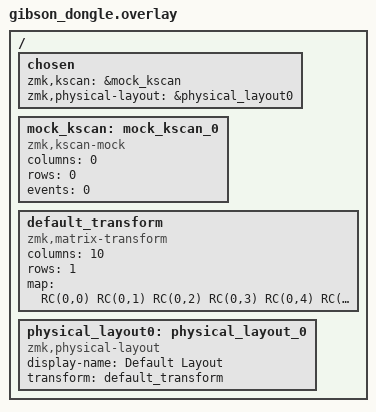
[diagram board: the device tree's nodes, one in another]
#include <dt-bindings/zmk/matrix_transform.h>

/ {
    chosen {
        zmk,kscan = &mock_kscan;
        zmk,physical-layout = &physical_layout0;
    };

    mock_kscan: mock_kscan_0 {
        compatible = "zmk,kscan-mock";
        columns = <0>;
        rows = <0>;
        events = <0>;
    };

    default_transform: default_transform {
        // See https://zmk.dev/docs/development/hardware-integration/new-shield#matrix-transform
        // for how to configure this
        compatible = "zmk,matrix-transform";
        columns = <10>;
        rows = <1>;
        //    L-pinky  L-ring  L-mid   L-idx   L-thumb  R-thumb R-idx   R-mid   R-ring  R-pinky
        map = <RC(0,0) RC(0,1) RC(0,2) RC(0,3) RC(0,4)  RC(0,5) RC(0,6) RC(0,7) RC(0,8) RC(0,9)>;
    };

    physical_layout0: physical_layout_0 {
        compatible = "zmk,physical-layout";
        display-name = "Default Layout";
        transform = <&default_transform>;
    };
};
